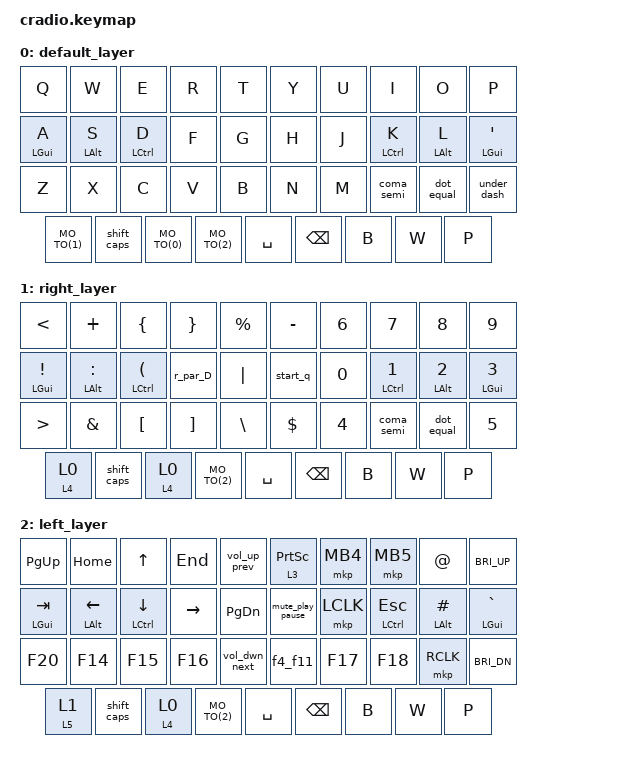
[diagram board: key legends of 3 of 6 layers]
// Copyright (c) 2022 The ZMK Contributors
// SPDX-License-Identifier: MIT

#include <behaviors.dtsi>
#include <dt-bindings/zmk/keys.h>
#include <dt-bindings/zmk/bt.h>
#include <dt-bindings/zmk/mouse.h>
#include <dt-bindings/zmk/outputs.h>

#define MO_TO(layer) &mo_to layer layer   // Macro to apply momentary-layer-on-hold/toggle-layer-on-tap to a specific layer


/ {
    combos {
        compatible = "zmk,combos";
        combo_undo {
            timeout-ms = <50>;
            key-positions = <20 21>;
            bindings = <&kp LC(Z)>;
            require-prior-idle-ms = <50>;
        };
        combo_copy {
            timeout-ms = <50>;
            key-positions = <21 22>;
            bindings = <&kp LC(C)>;
            require-prior-idle-ms = <50>;
        };
        combo_shift_copy {
            timeout-ms = <50>;
            key-positions = <21 22 31>;
            bindings = <&kp LS(LC(C))>;
        };
        combo_paste {
            timeout-ms = <50>;
            key-positions = <22 23>;
            bindings = <&kp LC(V)>;
            require-prior-idle-ms = <50>;
        };
        combo_shift_paste {
            timeout-ms = <50>;
            key-positions = <22 23 31>;
            bindings = <&kp LS(LC(V))>;
        };
        combo_cut {
            timeout-ms = <50>;
            key-positions = <23 24>;
            bindings = <&kp LC(X)>;
            require-prior-idle-ms = <50>;
        };
        combo_backspace {
            timeout-ms = <50>;
            key-positions = <12 13>;
            bindings = <&kp BSPC>;
            require-prior-idle-ms = <50>;
        };
        combo_backspace_2 {
            timeout-ms = <50>;
            key-positions = <13 14>;
            bindings = <&kp BSPC>;
        };
        combo_backspace_3 {
            timeout-ms = <50>;
            key-positions = <11 12>;
            bindings = <&kp BSPC>;
        };
        combo_delete {
            timeout-ms = <50>;
            key-positions = <16 17>;
            bindings = <&kp DEL>;
            require-prior-idle-ms = <50>;
        };
        combo_enter {
            timeout-ms = <100>;
            key-positions = <17 18>;
            bindings = <&kp ENTER>;
            require-prior-idle-ms = <50>;
        };
        combo_enter2 {
            timeout-ms = <100>;
            key-positions = <18 19>;
            bindings = <&kp ENTER>;
            require-prior-idle-ms = <50>;
        };
        combo_shift_enter {
            timeout-ms = <100>;
            key-positions = <17 18 31>;
            bindings = <&kp LS(ENTER)>;
            require-prior-idle-ms = <50>;
        };
        combo_shift_enter2 {
            timeout-ms = <100>;
            key-positions = <18 19 31>;
            bindings = <&kp LS(ENTER)>;
            require-prior-idle-ms = <50>;
        };
        combo_slash {
            timeout-ms = <100>;
            key-positions = <28 29>;
            bindings = <&kp SLASH>;
            require-prior-idle-ms = <50>;
        };
        combo_question {
            timeout-ms = <100>;
            key-positions = <28 29 31>;
            bindings = <&kp LS(SLASH)>;
            require-prior-idle-ms = <50>;
        };
        combo_third_layer {
            timeout-ms = <1000>;
            key-positions = <32 33>;
            bindings = <&mo_to 5 1>;
        };
        combo_reset_left {
            timeout-ms = <100>;
            key-positions = <0 1 2 3>;
            bindings = <&sys_reset>;
        };
    };


    behaviors {
        // for home row mods
        ht: hold_tap {
            compatible = "zmk,behavior-hold-tap";
            #binding-cells = <2>;
            flavor = "tap-preferred";
            tapping-term-ms = <270>;
            quick-tap-ms = <250>;
            require-prior-idle-ms = <100>;
            bindings = <&kp>, <&kp>;
        };
        // momentary or toggle layer switch
        mo_to: behavior_mo_to {
            compatible = "zmk,behavior-hold-tap";
            #binding-cells = <2>;
            flavor = "hold-preferred";
            tapping-term-ms = <200>;
            bindings = <&mo>, <&to>;
        };

        shift_caps: tap_dance_0 {
            compatible = "zmk,behavior-tap-dance";
            #binding-cells = <0>;
            tapping-term-ms = <400>;
            bindings = <&kp LSHIFT>, <&kp CAPS>;
        };

        coma_semi: coma_semi {
            compatible = "zmk,behavior-mod-morph";
            #binding-cells = <0>;
            bindings = <&kp COMMA>, <&kp SEMI>;
            mods = <(MOD_LSFT)>;
        };
        dot_equal: dot_equal {
            compatible = "zmk,behavior-mod-morph";
            #binding-cells = <0>;
            bindings = <&kp DOT>, <&kp EQUAL>;
            mods = <(MOD_LSFT)>;
        };
        under_dash: under_dash {
            compatible = "zmk,behavior-mod-morph";
            #binding-cells = <0>;
            bindings = <&kp UNDER>, <&kp MINUS>;
            mods = <(MOD_LSFT)>;
        };
        start_q: start_q {
            compatible = "zmk,behavior-mod-morph";
            #binding-cells = <0>;
            bindings = <&kp STAR>, <&kp LS(Q)>;
            mods = <(MOD_LSFT)>;
        };
        r_par_D: r_par_D {
            compatible = "zmk,behavior-mod-morph";
            #binding-cells = <0>;
            bindings = <&kp RPAR>, <&kp LS(D)>;
            mods = <(MOD_LSFT)>;
        };

        vol_up_prev: vol_up_prev {
            compatible = "zmk,behavior-mod-morph";
            #binding-cells = <0>;
            bindings = <&kp C_VOL_UP>, <&kp C_PREV>;
            mods = <(MOD_LSFT)>;
        };
        vol_dwn_next: vol_dwn_next {
            compatible = "zmk,behavior-mod-morph";
            #binding-cells = <0>;
            bindings = <&kp C_VOL_DN>, <&kp C_NEXT>;
            mods = <(MOD_LSFT)>;
        };
        mute_play_pause: mute_play_pause {
            compatible = "zmk,behavior-mod-morph";
            #binding-cells = <0>;
            bindings = <&kp C_MUTE>, <&kp C_PP>;
            mods = <(MOD_LSFT)>;
        };
        f4_f11: f4_f11 {
            compatible = "zmk,behavior-mod-morph";
            #binding-cells = <0>;
            bindings = <&kp F4>, <&kp F11>;
            mods = <(MOD_LSFT)>;
        };
    };


    keymap {
        compatible = "zmk,keymap";
        default_layer {
            bindings = <
        //╭──────────┬──────────┬──────────┬──────────┬──────────╮   ╭──────────┬──────────┬──────────┬──────────┬──────────╮
        //│  Q       │  W       │  E       │  R       │  T       │   │  Y       │  U       │  I       │  O       │  P       │
            &kp Q      &kp W      &kp E      &kp R      &kp T          &kp Y      &kp U      &kp I      &kp O      &kp P
        //├──────────┼──────────┼──────────┼──────────┼──────────┤   ├──────────┼──────────┼──────────┼──────────┼──────────┤
        //│  A       │  S       │  D       │  F       │  G       │   │  H       │  J       │  K       │  L       │  '  "    │
          &ht LGUI A  &ht LALT S  &ht LCTRL D   &kp F      &kp G          &kp H     &kp J  &ht LCTRL K  &ht LALT L   &ht LGUI SQT 
        //├──────────┼──────────┼──────────┼──────────┼──────────┤   ├──────────┼──────────┼──────────┼──────────┼──────────┤
        //│  Z       │  X       │  C       │  V       │  B       │   │  N       │  M       │ , ;      │ . =      │ _  -  /  │
            &kp Z      &kp X      &kp C      &kp V      &kp B          &kp N      &kp M    &coma_semi  &dot_equal    &under_dash 
        //╰──────────┴──────────┴──────────┼──────────┼──────────┤   ├──────────┼──────────┼──────────┴──────────┴──────────╯
                                 MO_TO(1)   &shift_caps  MO_TO(0)     MO_TO(2)   &kp SPACE   &kp BSPC       &kp B   &kp W   &kp P
        //                                 ╰──────────┴──────────╯   ╰──────────┴──────────╯
            >;
        };

        right_layer {
            bindings = <
        //╭──────────┬──────────┬──────────┬──────────┬──────────╮   ╭──────────┬──────────┬──────────┬──────────┬──────────╮
        //│  <       │  +       │	  {    │     }    │     %    │   │   -  _   │   6  ^   │    7     │   8      │    9     │
            &kp LT   &kp PLUS      &kp LBRC   &kp RBRC  &kp PRCNT      &kp MINUS   &kp N6    &kp N7      &kp N8    &kp N9   
        //├──────────┼──────────┼──────────┼──────────┼──────────┤   ├──────────┼──────────┼──────────┼──────────┼──────────┤
        //│   !      │ 	 :      │  (       │   )   D  │   |      │   │   *  Q   │   0      │  1       │   2      │  3       │
&ht LGUI EXCL  &ht LALT COLON  &ht LCTRL LPAR  &r_par_D  &kp PIPE   &start_q  &kp N0  &ht LCTRL N1  &ht LALT N2  &ht LGUI N3
        //├──────────┼──────────┼──────────┼──────────┼──────────┤   ├──────────┼──────────┼──────────┼──────────┼──────────┤
        //│    >     │  &       │  [       │  ]       │  \       │   │    $     │    4     │   , ;    │   . =    │   5      │
           &kp GT    &kp AMPS    &kp LBKT  &kp RBKT    &kp BSLH         &kp DLLR   &kp N4   &coma_semi  &dot_equal   &kp N5
        //╰──────────┴──────────┴──────────┼──────────┼──────────┤   ├──────────┼──────────┼──────────┴──────────┴──────────╯
                               &mo_to 4 0   &shift_caps  &mo_to 4 0     MO_TO(2)   &kp SPACE   &kp BSPC         &kp B   &kp W   &kp P
        //                                 ╰──────────┴──────────╯   ╰──────────┴──────────╯
            >;
        };

        left_layer {
            bindings = <
        //╭──────────┬──────────┬──────────┬──────────┬──────────╮   ╭──────────┬──────────┬──────────┬──────────┬──────────╮
        //│   PgUp   │  Home    │    UP    │  END     │ VolUpPrev│   │Scrn/UpLyr│ MousBtn4 │ MousBtn5 │    @     │ BrightUp │
         &kp PG_UP     &kp HOME   &kp UP   &kp END   &vol_up_prev     &lt 3 PSCRN  &mkp MB4  &mkp MB5   &kp AT    &kp C_BRI_UP
        //├──────────┼──────────┼──────────┼──────────┼──────────┤   ├──────────┼──────────┼──────────┼──────────┼──────────┤
        //│  TAB     │  Left    │  Down    │  RIGHT   │ PgDwn    │   | mute/Play│LeftMouse │    ESC   │    #     │   `  ~   │
&ht LGUI TAB   &ht LALT LEFT  &ht LCTRL DOWN  &kp RIGHT  &kp PG_DN    &mute_play_pause  &mkp LCLK  &ht LCTRL ESC  &ht LALT HASH   &ht LGUI GRAVE
        //├──────────┼──────────┼──────────┼──────────┼──────────┤   ├──────────┼──────────┼──────────┼──────────┼──────────┤
        //│   F20    │   F14    │   F15    │   F16    │VolDwnNext│   │ F4  F11  │   F17    |    F18   │RightMouse│ BrightDwn│
            &kp F20  &kp F14    &kp F15    &kp F16   &vol_dwn_next    &f4_f11     &kp F17      &kp F18  &mkp RCLK   &kp C_BRI_DN
        //╰──────────┴──────────┴──────────┼──────────┼──────────┤   ├──────────┼──────────┼──────────┴──────────┴──────────╯
                            &mo_to 5 1    &shift_caps  &mo_to 4 0      MO_TO(2)   &kp SPACE   &kp BSPC         &kp B   &kp W   &kp P
        //                                 ╰──────────┴──────────╯   ╰──────────┴──────────╯
            >;
        };

        tri_layer {
            bindings = <
        //╭──────────┬──────────┬──────────┬──────────┬──────────╮   ╭──────────┬──────────┬──────────┬──────────┬──────────╮
        //│  BT0     │  Bt1     │     BT2  │  BT3     | CLEAR BT │   │KeepUpLaye│          │          │          │          │
      &bt BT_SEL 0 &bt BT_SEL 1 &bt BT_SEL 2 &bt BT_SEL 3  &bt BT_CLR     &trans     &none     &none    &none      &none
        //├──────────┼──────────┼──────────┼──────────┼──────────┤   ├──────────┼──────────┼──────────┼──────────┼──────────┤
        //│USB BLE TG│          │          │          │          │   │          │          │          │          │          │
         &out OUT_TOG  &none     &none      &none        &none          &none     &none         &none   &none       &none    
        //├──────────┼──────────┼──────────┼──────────┼──────────┤   ├──────────┼──────────┼──────────┼──────────┼──────────┤
        //│ BtDiscon0| BtDiscon1│ BtDiscon2│ RESET    │BOOTLOADER│   │BOOTLOADER│ RESET    │          │          │          │
        &bt BT_DISC 0 &bt BT_DISC 1 &bt BT_DISC 2 &sys_reset &bootloader    &bootloader  &sys_reset   &none     &none     &none
        //╰──────────┴──────────┴──────────┼──────────┼──────────┤   ├──────────┼──────────┼──────────┴──────────┴──────────╯
                                    &none        &none     &none         &none     &none    &none   
        //                                 ╰──────────┴──────────╯   ╰──────────┴──────────╯
            >;
        };
        
        copy_default_layer {
            bindings = <
        //╭──────────┬──────────┬──────────┬──────────┬──────────╮   ╭──────────┬──────────┬──────────┬──────────┬──────────╮
        //│  Q       │  W       │  E       │  R       │  T       │   │  Y       │  U       │  I       │  O       │  P       │
            &kp Q      &kp W      &kp E      &kp R      &kp T          &kp Y      &kp U      &kp I      &kp O      &kp P
        //├──────────┼──────────┼──────────┼──────────┼──────────┤   ├──────────┼──────────┼──────────┼──────────┼──────────┤
        //│  A       │  S       │  D       │  F       │  G       │   │  H       │  J       │  K       │  L       │  '  "    │
          &ht LGUI A  &ht LALT S  &ht LCTRL D   &kp F      &kp G          &kp H     &kp J  &ht LCTRL K  &ht LALT L   &ht LGUI SQT 
        //├──────────┼──────────┼──────────┼──────────┼──────────┤   ├──────────┼──────────┼──────────┼──────────┼──────────┤
        //│  Z       │  X       │  C       │  V       │  B       │   │  N       │  M       │ , ;      │ . =      │ _  -  /  │
            &kp Z      &kp X      &kp C      &kp V      &kp B          &kp N      &kp M    &coma_semi  &dot_equal    &under_dash 
        //╰──────────┴──────────┴──────────┼──────────┼──────────┤   ├──────────┼──────────┼──────────┴──────────┴──────────╯
        // ********************* IF YOU UPDATE THE KEYMAP, DON'T CHANGE THE THUMBS. ************************
                                 MO_TO(1)   &shift_caps  MO_TO(0)     MO_TO(2)   &kp SPACE   &kp BSPC  
        //                                 ╰──────────┴──────────╯   ╰──────────┴──────────╯
            >;
        };
        
        copy_right_layer {
            bindings = <
        //╭──────────┬──────────┬──────────┬──────────┬──────────╮   ╭──────────┬──────────┬──────────┬──────────┬──────────╮
        //│  <       │  +       │	  {    │     }    │     %    │   │   -  _   │   6  ^   │    7     │   8      │    9     │
            &kp LT   &kp PLUS      &kp LBRC   &kp RBRC  &kp PRCNT      &kp MINUS   &kp N6    &kp N7      &kp N8    &kp N9   
        //├──────────┼──────────┼──────────┼──────────┼──────────┤   ├──────────┼──────────┼──────────┼──────────┼──────────┤
        //│   !      │ 	 :      │  (       │   )   D  │   |      │   │   *  Q   │   0      │  1       │   2      │  3       │
 &ht LGUI EXCL  &ht LALT COLON  &ht LCTRL LPAR  &r_par_D  &kp PIPE   &start_q  &kp N0  &ht LCTRL N1  &ht LALT N2  &ht LGUI N3
        //├──────────┼──────────┼──────────┼──────────┼──────────┤   ├──────────┼──────────┼──────────┼──────────┼──────────┤
        //│    >     │  &       │  [       │  ]       │  \       │   │    $     │    4     │   , ;    │   . =    │   5      │
           &kp GT    &kp AMPS    &kp LBKT  &kp RBKT    &kp BSLH         &kp DLLR   &kp N4   &coma_semi  &dot_equal   &kp N5
        //╰──────────┴──────────┴──────────┼──────────┼──────────┤   ├──────────┼──────────┼──────────┴──────────┴──────────╯
        // ********************* IF YOU UPDATE THE KEYMAP, DON'T CHANGE THE THUMBS. ************************
                                 MO_TO(1)   &shift_caps  MO_TO(0)     MO_TO(2)   &kp SPACE   &kp BSPC  
        //                                 ╰──────────┴──────────╯   ╰──────────┴──────────╯
            >;
        };
    };
};

